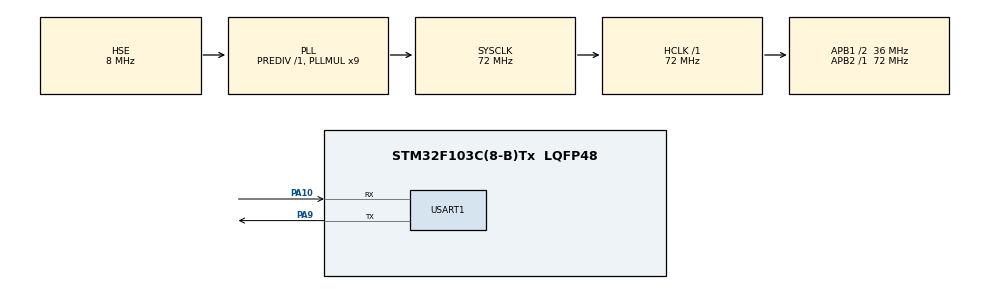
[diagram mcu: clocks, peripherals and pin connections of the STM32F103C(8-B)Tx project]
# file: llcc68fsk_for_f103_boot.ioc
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Dma.Request0=USART1_RX
Dma.Request1=USART1_TX
Dma.USART1_RX.0.Direction=DMA_PERIPH_TO_MEMORY
Dma.USART1_RX.0.Instance=DMA1_Channel5
Dma.USART1_RX.0.MemDataAlignment=DMA_MDATAALIGN_BYTE
Dma.USART1_RX.0.MemInc=DMA_MINC_ENABLE
Dma.USART1_RX.0.Mode=DMA_CIRCULAR
Dma.USART1_RX.0.PeriphDataAlignment=DMA_PDATAALIGN_BYTE
Dma.USART1_RX.0.PeriphInc=DMA_PINC_DISABLE
Dma.USART1_RX.0.Priority=DMA_PRIORITY_LOW
Dma.USART1_TX.1.Direction=DMA_MEMORY_TO_PERIPH
Dma.USART1_TX.1.Instance=DMA1_Channel4
Dma.USART1_TX.1.MemDataAlignment=DMA_MDATAALIGN_BYTE
Dma.USART1_TX.1.MemInc=DMA_MINC_ENABLE
Dma.USART1_TX.1.Mode=DMA_NORMAL
Dma.USART1_TX.1.PeriphDataAlignment=DMA_PDATAALIGN_BYTE
Dma.USART1_TX.1.PeriphInc=DMA_PINC_DISABLE
Dma.USART1_TX.1.Priority=DMA_PRIORITY_LOW
Mcu.Family=STM32F1
Mcu.Name=STM32F103C(8-B)Tx
Mcu.Package=LQFP48
NVIC.DMA1_Channel4_IRQn=true\:1\:0\:true\:false\:true\:false\:true\:true
NVIC.DMA1_Channel5_IRQn=true\:1\:0\:true\:false\:true\:false\:true\:true
NVIC.PriorityGroup=NVIC_PRIORITYGROUP_4
NVIC.USART1_IRQn=true\:1\:0\:true\:false\:true\:false\:true\:true
PA10.Mode=Asynchronous
PA10.Signal=USART1_RX
PA13.Mode=Serial_Wire
PA13.Signal=SYS_JTMS-SWDIO
PA14.Mode=Serial_Wire
PA14.Signal=SYS_JTCK-SWCLK
PA9.Mode=Asynchronous
PA9.Signal=USART1_TX
PD0-OSC_IN.Mode=HSE-External-Oscillator
PD0-OSC_IN.Signal=RCC_OSC_IN
PD1-OSC_OUT.Mode=HSE-External-Oscillator
PD1-OSC_OUT.Signal=RCC_OSC_OUT
ProjectManager.HeapSize=0x200
ProjectManager.StackSize=0x400
ProjectManager.TargetToolchain=CMake
RCC.AHBFreq_Value=72000000
RCC.APB1CLKDivider=RCC_HCLK_DIV2
RCC.APB1Freq_Value=36000000
RCC.APB1TimFreq_Value=72000000
RCC.APB2Freq_Value=72000000
RCC.APB2TimFreq_Value=72000000
RCC.HCLKFreq_Value=72000000
RCC.PLLMUL=RCC_PLL_MUL9
RCC.PLLSourceVirtual=RCC_PLLSOURCE_HSE
RCC.SYSCLKFreq_VALUE=72000000
RCC.SYSCLKSource=RCC_SYSCLKSOURCE_PLLCLK
RCC.USBFreq_Value=72000000
USART1.VirtualMode=VM_ASYNC
board=custom

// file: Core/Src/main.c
/* USER CODE BEGIN Header */
/**
  ******************************************************************************
  * @file           : main.c
  * @brief          : Main program body
  ******************************************************************************
  * @attention
  *
  * Copyright (c) 2026 STMicroelectronics.
  * All rights reserved.
  *
  * This software is licensed under terms that can be found in the LICENSE file
  * in the root directory of this software component.
  * If no LICENSE file comes with this software, it is provided AS-IS.
  *
  ******************************************************************************
  */
/* USER CODE END Header */
#include "main.h"
#include "dma.h"
#include "stm32f1xx_hal_uart.h"
#include "update.h"
#include "usart.h"
#include "gpio.h"

/* USER CODE BEGIN Includes */
#include "flash_layout.h"
#include "update_uart.h"
#include "ymodem.h"
#include <stdbool.h>
#include <stdint.h>
#include <stdio.h>
/* USER CODE END Includes */

/* USER CODE BEGIN PV */
volatile COM_StatusTypeDef g_upgrade_status = COM_ERROR;  // 升级状态
volatile uint32_t g_upgrade_size = 0;                     // 升级文件大小

// 写入目标应用程序的起始地址和大小
uint32_t app_base = APP_A_BASE;
uint32_t app_size = APP_SIZE;
// 获取到固件文件标志
bool firmware_received = false;
// 程序损坏标志
bool app_corrupted = false;

/* USER CODE END PV */

void SystemClock_Config(void);
/* USER CODE BEGIN PFP */
extern bool boot_jump(uint32_t base);

/* 保留原扇区擦除函数；F103 HAL 没有该接口，本芯片不编译它。 */
#if defined(FLASH_TYPEERASE_SECTORS)
// 擦除flash扇区
static void Flash_Erase_Sector(uint32_t sector)
{
    FLASH_EraseInitTypeDef EraseInitStruct = {0};
    uint32_t SectorError = 0;

    // 配置擦除参数
    EraseInitStruct.TypeErase = FLASH_TYPEERASE_SECTORS; // 按扇区擦除
    EraseInitStruct.Banks = FLASH_BANK_1; // 对于单BANK芯片
    EraseInitStruct.Sector = sector;      // 要擦除的扇区号
    EraseInitStruct.NbSectors = 1;        // 擦除1个扇区
    EraseInitStruct.VoltageRange = FLASH_VOLTAGE_RANGE_3; // 电压范围，通常为3

    // 执行擦除，并检查错误
    if (HAL_FLASHEx_Erase(&EraseInitStruct, &SectorError) != HAL_OK) {
        // SectorError会返回出错的扇区号
        Error_Handler();
    }
}
#endif

/* F103 按页擦除；调用前必须解锁 Flash。 */
static bool Flash_Erase_Pages(uint32_t start, uint32_t page_count)
{
  FLASH_EraseInitTypeDef erase = {0}; // 擦除参数结构体
  uint32_t page_error = 0;            // 擦除错误页号

  erase.TypeErase = FLASH_TYPEERASE_PAGES;  // 按页擦除
  erase.Banks = FLASH_BANK_1;               // 对于单BANK芯片
  erase.PageAddress = start;                // 起始页地址
  erase.NbPages = page_count;               // 擦除页数
  // 执行擦除，并检查错误
  return HAL_FLASHEx_Erase(&erase, &page_error) == HAL_OK;
}

// 将程序包写入flash
static bool write_flash(void *context, update_event_t event,
                                  const update_file_t *file,
                                  uint32_t offset,
                                  const uint8_t *data,
                                  uint16_t length)
{
  static uint32_t next_offset;  // 下一个预期的偏移量
  static bool erased;
  (void)context;

  if (event == UPDATE_EVENT_HEADER)
  {
    firmware_received = true;
    erased = false;
    next_offset = 0;
    if (file == NULL || file->size == 0u || file->size > app_size ||
        (app_base % PAGE_SIZE) != 0u)
    {
      return false;
    }
    /* 向上取整，只擦除文件占用的页。 */
    uint32_t page_count = (file->size - 1u) / PAGE_SIZE + 1u;
    if (HAL_FLASH_Unlock() != HAL_OK)
    {
      return false;
    }
    if (!Flash_Erase_Pages(app_base, page_count))
    {
      return false;
    }
    erased = true;
    return true;
  }
  else if (event == UPDATE_EVENT_DATA)
  {
    if (!erased || file == NULL || data == NULL || length == 0u ||
        file->size > app_size || offset != next_offset ||
        offset > file->size || length > file->size - offset ||
        (offset & 1u) != 0u)
    {
      return false;
    }
    /* F103 每次写入 16 位；文件末尾不足 16 位时用 0xFF 填高字节。 */
    for (uint32_t i = 0; i < length; i += 2u)
    {
      uint16_t high = (i + 1u < length) ? data[i + 1u] : 0xFFu;
      uint16_t value = (uint16_t)data[i] | (uint16_t)(high << 8);
      uint32_t address = app_base + offset + i;
      if (HAL_FLASH_Program(FLASH_TYPEPROGRAM_HALFWORD, address, value) != HAL_OK ||
          *(volatile const uint16_t *)address != value)
      {
        return false;
      }
    }
    next_offset += length;
    return true;
  }
  return false;
}
/* USER CODE END PFP */

int main(void)
{

  /* MCU Configuration--------------------------------------------------------*/

  /* Reset of all peripherals, Initializes the Flash interface and the Systick. */
  HAL_Init();

  /* Configure the system clock */
  SystemClock_Config();

  /* Initialize all configured peripherals */
  MX_GPIO_Init();
  MX_DMA_Init();
  MX_USART1_UART_Init();
  /* USER CODE BEGIN 2 */

  update_file_t file = {0};
  HAL_FLASH_Unlock(); /* 接收前解锁 Flash，接收失败或成功后重新锁定。 */
  update_result_t result = update_receive_uart(&huart1,
    app_size,
    &file,
    write_flash,
    NULL);
  HAL_FLASH_Lock(); /* 接收成功或失败后都重新锁定 Flash。 */
  if (result != UPDATE_OK && firmware_received)
  {
    // 接收到固件文件，但没有完成固件升级，说明出错
    g_upgrade_status = COM_ERROR;
    g_upgrade_size = 0;
    app_corrupted = true; /* 接收失败，程序可能损坏。 */
  }
  else if (false == firmware_received)
  {
    // 没有接收到固件文件，可以直接跳转到原来的程序
    app_corrupted = false;
    HAL_UART_Transmit(&huart1,
      (uint8_t *)"【INFO】未接收到固件文件，跳转到原程序...\r\n",
      60,
      HAL_MAX_DELAY);
  }
  else
  {
    // 接收成功，固件升级完成
    g_upgrade_status = COM_OK;
    g_upgrade_size = file.size;
    HAL_UART_Transmit(&huart1,
      (uint8_t *)"【INFO】升级成功，跳转到新程序...\r\n",
      48,
      HAL_MAX_DELAY);
    app_corrupted = false;
  }
  /* Activation and rollback metadata are separate from file reception. */
  if (app_corrupted)
  {
    HAL_UART_Transmit(&huart1,
      (uint8_t *)"【INFO】升级失败，请复位重试。\r\n",
      50,
      HAL_MAX_DELAY);
    while (1)
    {
      HAL_Delay(1000);
    }
  }
  boot_jump(APP_A_BASE);

  /* If App A is invalid, keep the serial recovery path available. */

  /* USER CODE END 2 */

  /* Infinite loop */
  while (1)
  {

  }
}

void SystemClock_Config(void)
{
  RCC_OscInitTypeDef RCC_OscInitStruct = {0};
  RCC_ClkInitTypeDef RCC_ClkInitStruct = {0};

  /** Initializes the RCC Oscillators according to the specified parameters
  * in the RCC_OscInitTypeDef structure.
  */
  RCC_OscInitStruct.OscillatorType = RCC_OSCILLATORTYPE_HSE;
  RCC_OscInitStruct.HSEState = RCC_HSE_ON;
  RCC_OscInitStruct.HSEPredivValue = RCC_HSE_PREDIV_DIV1;
  RCC_OscInitStruct.HSIState = RCC_HSI_ON;
  RCC_OscInitStruct.PLL.PLLState = RCC_PLL_ON;
  RCC_OscInitStruct.PLL.PLLSource = RCC_PLLSOURCE_HSE;
  RCC_OscInitStruct.PLL.PLLMUL = RCC_PLL_MUL9;
  if (HAL_RCC_OscConfig(&RCC_OscInitStruct) != HAL_OK)
  {
    Error_Handler();
  }

  /** Initializes the CPU, AHB and APB buses clocks
  */
  RCC_ClkInitStruct.ClockType = RCC_CLOCKTYPE_HCLK|RCC_CLOCKTYPE_SYSCLK
                              |RCC_CLOCKTYPE_PCLK1|RCC_CLOCKTYPE_PCLK2;
  RCC_ClkInitStruct.SYSCLKSource = RCC_SYSCLKSOURCE_PLLCLK;
  RCC_ClkInitStruct.AHBCLKDivider = RCC_SYSCLK_DIV1;
  RCC_ClkInitStruct.APB1CLKDivider = RCC_HCLK_DIV2;
  RCC_ClkInitStruct.APB2CLKDivider = RCC_HCLK_DIV1;

  if (HAL_RCC_ClockConfig(&RCC_ClkInitStruct, FLASH_LATENCY_2) != HAL_OK)
  {
    Error_Handler();
  }
}

void Error_Handler(void)
{
  __disable_irq();
  while (1)
  {
  }
}
